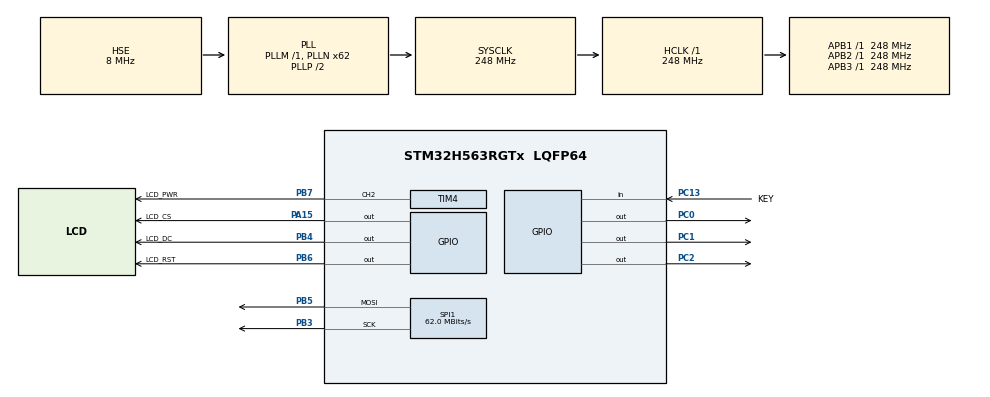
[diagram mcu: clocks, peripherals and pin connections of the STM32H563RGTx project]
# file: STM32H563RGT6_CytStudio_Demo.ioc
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BOOTPATH.BootPathName=LEGACY
BOOTPATH.UserSelectedBootPath=LEGACY
CORTEX_M33_NS.AccessPermission_OTP_RO_AREAS=MPU_REGION_ALL_RO
CORTEX_M33_NS.DisableExec_OTP_RO_AREAS=MPU_INSTRUCTION_ACCESS_DISABLE
CORTEX_M33_NS.Enable-Cortex_Memory_Protection_Unit_Region1_Settings=__NULL
CORTEX_M33_NS.Enable_OTP_RO_AREAS=MPU_REGION_ENABLE
CORTEX_M33_NS.MPU_Control=MPU_PRIVILEGED_DEFAULT
CORTEX_M33_NS.Number-Cortex_Memory_Protection_Unit_Region0_OTP_RO_AREAS_Settings=MPU_REGION_NUMBER0
CORTEX_M33_NS.default_mode_Activation=1
CORTEX_M33_NS.userName=CORTEX_M33
GPDMA1.DESTDATAWIDTH_GPDMACH0=DMA_DEST_DATAWIDTH_HALFWORD
GPDMA1.DIRECTION_GPDMACH0=DMA_MEMORY_TO_PERIPH
GPDMA1.IPHANDLE_GPDMACH0-SIMPLEREQUEST_GPDMACH0=__NULL
GPDMA1.REQUEST_GPDMACH0=GPDMA1_REQUEST_SPI1_TX
GPDMA1.SRCDATAWIDTH_GPDMACH0=DMA_SRC_DATAWIDTH_HALFWORD
GPDMA1.SRCINC_GPDMACH0=DMA_SINC_INCREMENTED
Mcu.Family=STM32H5
Mcu.Name=STM32H563RGTx
Mcu.Package=LQFP64
NVIC.GPDMA1_Channel0_IRQn=true\:0\:0\:true\:false\:true\:true\:true\:true
NVIC.PriorityGroup=NVIC_PRIORITYGROUP_4
NVIC.SPI1_IRQn=true\:0\:0\:true\:false\:true\:true\:true\:true
PA13(JTMS/SWDIO).Mode=Serial_Wire
PA13(JTMS/SWDIO).Signal=DEBUG_JTMS-SWDIO
PA14(JTCK/SWCLK).Mode=Serial_Wire
PA14(JTCK/SWCLK).Signal=DEBUG_JTCK-SWCLK
PA15(JTDI).GPIO_Label=LCD_CS
PA15(JTDI).GPIO_Speed=GPIO_SPEED_FREQ_VERY_HIGH
PA15(JTDI).PinState=GPIO_PIN_SET
PA15(JTDI).Signal=GPIO_Output
PB3(JTDO/TRACESWO).GPIO_Speed=GPIO_SPEED_FREQ_VERY_HIGH
PB3(JTDO/TRACESWO).Mode=TX_Only_Simplex_Unidirect_Master
PB3(JTDO/TRACESWO).Signal=SPI1_SCK
PB4(NJTRST).GPIO_Label=LCD_DC
PB4(NJTRST).GPIO_Speed=GPIO_SPEED_FREQ_VERY_HIGH
PB4(NJTRST).PinState=GPIO_PIN_RESET
PB4(NJTRST).Signal=GPIO_Output
PB5.GPIO_Speed=GPIO_SPEED_FREQ_VERY_HIGH
PB5.Mode=TX_Only_Simplex_Unidirect_Master
PB5.Signal=SPI1_MOSI
PB6.GPIO_Label=LCD_RST
PB6.GPIO_Speed=GPIO_SPEED_FREQ_VERY_HIGH
PB6.PinState=GPIO_PIN_SET
PB6.Signal=GPIO_Output
PB7.GPIO_FM7=SBS_FASTMODEPLUS_PB7
PB7.GPIO_Label=LCD_PWR
PB7.GPIO_PuPd=GPIO_PULLUP
PB7.GPIO_Speed=GPIO_SPEED_FREQ_HIGH
PB7.Signal=S_TIM4_CH2
PC0.PinState=GPIO_PIN_SET
PC0.Signal=GPIO_Output
PC1.PinState=GPIO_PIN_SET
PC1.Signal=GPIO_Output
PC13.GPIO_Label=KEY
PC13.GPIO_PuPd=GPIO_PULLUP
PC13.Signal=GPIO_Input
PC14-OSC32_IN(OSC32_IN).Mode=LSE-External-Oscillator
PC14-OSC32_IN(OSC32_IN).Signal=RCC_OSC32_IN
PC15-OSC32_OUT(OSC32_OUT).Mode=LSE-External-Oscillator
PC15-OSC32_OUT(OSC32_OUT).Signal=RCC_OSC32_OUT
PC2.PinState=GPIO_PIN_SET
PC2.Signal=GPIO_Output
PH0-OSC_IN(PH0).Mode=HSE-External-Oscillator
PH0-OSC_IN(PH0).Signal=RCC_OSC_IN
PH1-OSC_OUT(PH1).Mode=HSE-External-Oscillator
PH1-OSC_OUT(PH1).Signal=RCC_OSC_OUT
ProjectManager.HeapSize=0x200
ProjectManager.StackSize=0x800
ProjectManager.TargetToolchain=STM32CubeIDE
RCC.ADCFreq_Value=248000000
RCC.AHBFreq_Value=248000000
RCC.APB1Freq_Value=248000000
RCC.APB1TimFreq_Value=248000000
RCC.APB2Freq_Value=248000000
RCC.APB2TimFreq_Value=248000000
RCC.APB3Freq_Value=248000000
RCC.CSI_VALUE=4000000
RCC.CortexFreq_Value=248000000
RCC.EPOD_VALUE=8000000
RCC.HCLKFreq_Value=248000000
RCC.HSE_VALUE=8000000
RCC.HSI48_VALUE=48000000
RCC.HSI_VALUE=64000000
RCC.LSIRC_VALUE=32000
RCC.PLL1Q=4
RCC.PLLFRACN=0
RCC.PLLN=62
RCC.PLLSourceVirtual=RCC_PLL1_SOURCE_HSE
RCC.SYSCLKFreq_VALUE=248000000
RCC.SYSCLKSource=RCC_SYSCLKSOURCE_PLLCLK
RCC.USBFreq_Value=48000000
RCC.VCOOutputFreq_Value=496000000
SH.S_TIM4_CH2.0=TIM4_CH2,PWM Generation2 CH2
SPI1.BaudRatePrescaler=SPI_BAUDRATEPRESCALER_2
SPI1.CalculateBaudRate=62.0 MBits/s
SPI1.DataSize=SPI_DATASIZE_8BIT
SPI1.Direction=SPI_DIRECTION_2LINES_TXONLY
SPI1.Mode=SPI_MODE_MASTER
SPI1.NSSPMode=SPI_NSS_PULSE_DISABLE
SPI1.VirtualType=VM_MASTER
TIM4.Channel-PWM\ Generation2\ CH2=TIM_CHANNEL_2
TIM4.PeriodNoDither=799
TIM4.Prescaler=61
VP_BOOTPATH_VS_BOOTPATH.Mode=BP_Activate
VP_CORTEX_M33_NS_VS_Hclk.Mode=Hclk_Mode
VP_FLASH_SIG_Activate_FlashIP.Mode=Activate_FlashIP
VP_GPDMA1_VS_GPDMACH0.Mode=SIMPLEREQUEST_GPDMACH0
VP_ICACHE_VS_ICACHE.Mode=DirectMappedCache
VP_MEMORYMAP_VS_MEMORYMAP.Mode=CurAppReg
VP_PWR_VS_LPOM.Mode=PowerOptimisation
VP_PWR_VS_SECSignals.Mode=Security/Privilege
VP_TIM4_VS_ClockSourceINT.Mode=Internal
board=custom

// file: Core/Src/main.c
/* USER CODE BEGIN Header */
/**
  ******************************************************************************
  * @file           : main.c
  * @brief          : Main program body
  ******************************************************************************
  * @attention
  *
  * Copyright (c) 2026 STMicroelectronics.
  * All rights reserved.
  *
  * This software is licensed under terms that can be found in the LICENSE file
  * in the root directory of this software component.
  * If no LICENSE file comes with this software, it is provided AS-IS.
  *
  ******************************************************************************
  */
/* USER CODE END Header */
#include "main.h"
#include "flash.h"
#include "gpdma.h"
#include "icache.h"
#include "spi.h"
#include "tim.h"
#include "gpio.h"

/* USER CODE BEGIN Includes */
/* Code added inside the USER CODE sections of this project is
   Apache-2.0, Copyright (C) 2026 CytStudio <cyte_studio@foxmail.com>.
   The rest of this file is STMicroelectronics BSD-3-Clause, see
   Drivers/STM32H5xx_HAL_Driver/LICENSE.txt. */
#include "app.h"
/* USER CODE END Includes */

void SystemClock_Config(void);
static void MPU_Config(void);

int main(void)
{

  /* MCU Configuration--------------------------------------------------------*/

  /* MPU Configuration--------------------------------------------------------*/
  MPU_Config();

  /* Reset of all peripherals, Initializes the Flash interface and the Systick. */
  HAL_Init();

  /* Configure the system clock */
  SystemClock_Config();

  /* USER CODE BEGIN SysInit */
  /* --- 248MHz / VOS0 下必须用 6 个 FLASH 等待周期，请勿改回 5 ------------
     CubeMX 从时钟树推导出的是 FLASH_LATENCY_5（手册下限，零余量）。但开 ICACHE
     之后每次 miss 都要对 flash 做一次 128bit(16 字节) 整行 burst 读，这种访问
     形态比按需窄读（关 ICACHE 时 32/64bit）更吃力；实测 5 WS 时 flash 会偶发
     整字 ECC 双比特错，被 H5 重定向成 NMI —— 见 SBS->ECCNMIR（复位默认不屏蔽），
     表现为界面跑几秒后突然死机（旧 NMI_Handler 是空 while(1)）。
     补一个等待周期即可（代价约几个百分点）；关 ICACHE 也能规避但性能损失大得多。

     * 这一行放在 USER CODE 区，是为了让 CubeMX 重新生成 main.c 时不会被
       FLASH_LATENCY_5 覆盖掉 —— 重新生成后 SystemClock_Config() 会先按 5 配置，
       随后这里再补到 6（运行中切换到更多等待周期是安全的）。
     * 诊断/取证代码见 Core/Src/stm32h5xx_it.c 里的 NMI_Handler（ECC 现场捕获）。 */
  __HAL_FLASH_SET_LATENCY(FLASH_LATENCY_6);
  while (__HAL_FLASH_GET_LATENCY() != FLASH_LATENCY_6)
  {
  }
  /* USER CODE END SysInit */

  /* Initialize all configured peripherals */
  MX_GPIO_Init();
  MX_GPDMA1_Init();
  MX_SPI1_Init();
  MX_ICACHE_Init();
  MX_FLASH_Init();
  MX_TIM4_Init();
  /* USER CODE BEGIN 2 */
  /* GPIO、GPDMA1_Channel0 和 SPI1 上面已经由 .ioc 生成的初始化配好了，
     BSP 只拿 hspi1 用。 */
  if (app_init() != 0)
  {
    Error_Handler();
  }
  /* USER CODE END 2 */

  /* Infinite loop */
  while (1)
  {

    /* USER CODE BEGIN 3 */
    app_run();
  }
  /* USER CODE END 3 */
}

void SystemClock_Config(void)
{
  RCC_OscInitTypeDef RCC_OscInitStruct = {0};
  RCC_ClkInitTypeDef RCC_ClkInitStruct = {0};

  /** Configure the main internal regulator output voltage
  */
  __HAL_PWR_VOLTAGESCALING_CONFIG(PWR_REGULATOR_VOLTAGE_SCALE0);

  while(!__HAL_PWR_GET_FLAG(PWR_FLAG_VOSRDY)) {}

  /** Initializes the RCC Oscillators according to the specified parameters
  * in the RCC_OscInitTypeDef structure.
  */
  RCC_OscInitStruct.OscillatorType = RCC_OSCILLATORTYPE_HSE;
  RCC_OscInitStruct.HSEState = RCC_HSE_ON;
  RCC_OscInitStruct.PLL.PLLState = RCC_PLL_ON;
  RCC_OscInitStruct.PLL.PLLSource = RCC_PLL1_SOURCE_HSE;
  RCC_OscInitStruct.PLL.PLLM = 1;
  RCC_OscInitStruct.PLL.PLLN = 62;
  RCC_OscInitStruct.PLL.PLLP = 2;
  RCC_OscInitStruct.PLL.PLLQ = 4;
  RCC_OscInitStruct.PLL.PLLR = 2;
  RCC_OscInitStruct.PLL.PLLRGE = RCC_PLL1_VCIRANGE_3;
  RCC_OscInitStruct.PLL.PLLVCOSEL = RCC_PLL1_VCORANGE_WIDE;
  RCC_OscInitStruct.PLL.PLLFRACN = 0;
  if (HAL_RCC_OscConfig(&RCC_OscInitStruct) != HAL_OK)
  {
    Error_Handler();
  }

  /** Initializes the CPU, AHB and APB buses clocks
  */
  RCC_ClkInitStruct.ClockType = RCC_CLOCKTYPE_HCLK|RCC_CLOCKTYPE_SYSCLK
                              |RCC_CLOCKTYPE_PCLK1|RCC_CLOCKTYPE_PCLK2
                              |RCC_CLOCKTYPE_PCLK3;
  RCC_ClkInitStruct.SYSCLKSource = RCC_SYSCLKSOURCE_PLLCLK;
  RCC_ClkInitStruct.AHBCLKDivider = RCC_SYSCLK_DIV1;
  RCC_ClkInitStruct.APB1CLKDivider = RCC_HCLK_DIV1;
  RCC_ClkInitStruct.APB2CLKDivider = RCC_HCLK_DIV1;
  RCC_ClkInitStruct.APB3CLKDivider = RCC_HCLK_DIV1;

  if (HAL_RCC_ClockConfig(&RCC_ClkInitStruct, FLASH_LATENCY_5) != HAL_OK)
  {
    Error_Handler();
  }

  /** Configure the programming delay
  */
  __HAL_FLASH_SET_PROGRAM_DELAY(FLASH_PROGRAMMING_DELAY_2);
}

 /* MPU Configuration */

void MPU_Config(void)
{
  MPU_Region_InitTypeDef MPU_InitStruct = {0};
  MPU_Attributes_InitTypeDef MPU_AttributesInit = {0};

  /* Disables the MPU */
  HAL_MPU_Disable();

  /** Initializes and configures the Region 0 and the memory to be protected
  */
  MPU_InitStruct.Enable = MPU_REGION_ENABLE;
  MPU_InitStruct.Number = MPU_REGION_NUMBER0;
  MPU_InitStruct.BaseAddress = 0x08FFF000;
  MPU_InitStruct.LimitAddress = 0x08FFFFFF;
  MPU_InitStruct.AttributesIndex = MPU_ATTRIBUTES_NUMBER0;
  MPU_InitStruct.AccessPermission = MPU_REGION_ALL_RO;
  MPU_InitStruct.DisableExec = MPU_INSTRUCTION_ACCESS_DISABLE;
  MPU_InitStruct.IsShareable = MPU_ACCESS_NOT_SHAREABLE;

  HAL_MPU_ConfigRegion(&MPU_InitStruct);

  /** Initializes and configures the Attribute 0 and the memory to be protected
  */
  MPU_AttributesInit.Number = MPU_ATTRIBUTES_NUMBER0;
  MPU_AttributesInit.Attributes = INNER_OUTER(MPU_NOT_CACHEABLE);

  HAL_MPU_ConfigMemoryAttributes(&MPU_AttributesInit);
  /* Enables the MPU */
  HAL_MPU_Enable(MPU_PRIVILEGED_DEFAULT);

}

void Error_Handler(void)
{
  __disable_irq();
  while (1)
  {
  }
}
